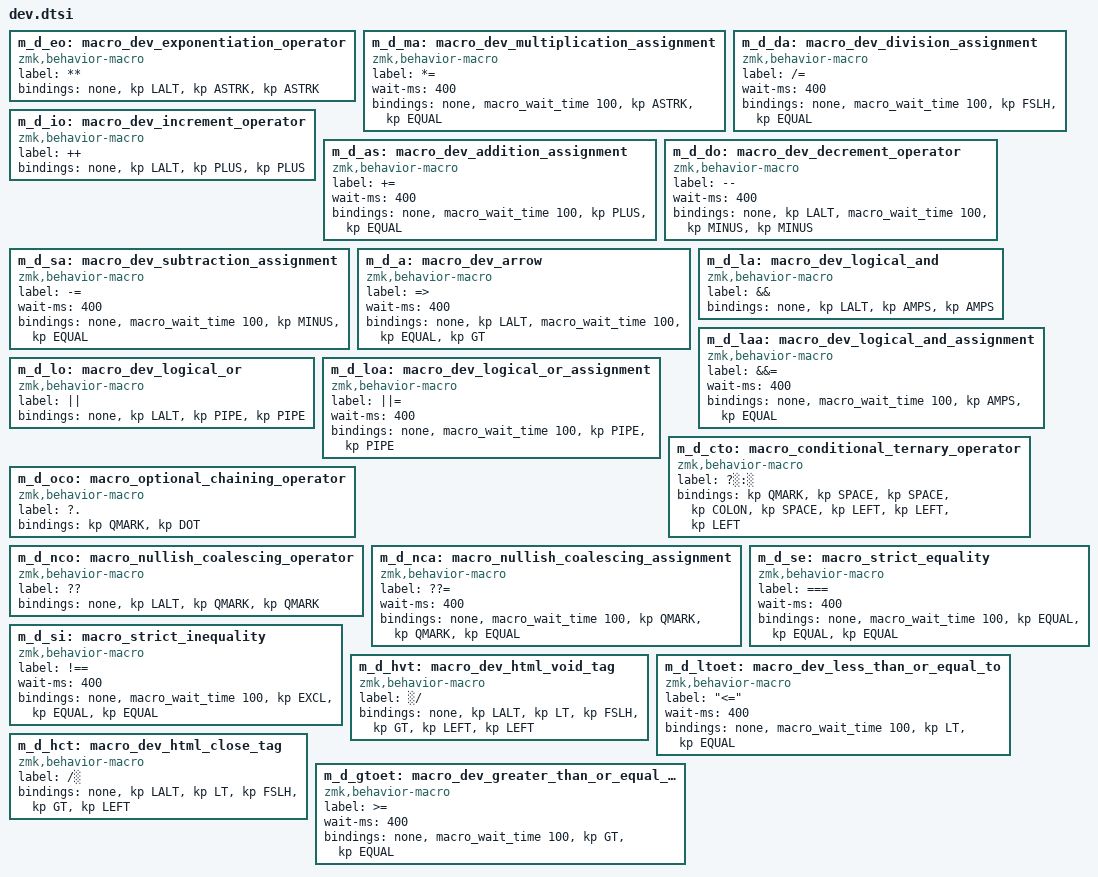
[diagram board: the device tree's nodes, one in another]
m_d_eo: macro_dev_exponentiation_operator {
    compatible = "zmk,behavior-macro";
    label = "**";
    #binding-cells = <0>;
    bindings
        = <&none &kp LALT> /* ALT fix for VSCode */
        , <&kp ASTRK &kp ASTRK>;
};

m_d_ma: macro_dev_multiplication_assignment {
    compatible = "zmk,behavior-macro";
    label = "*=";
    #binding-cells = <0>;
    wait-ms = <400>;
    bindings
        = <&none>
        , <&macro_wait_time 100>
        , <&kp ASTRK &kp EQUAL>;
};

m_d_da: macro_dev_division_assignment {
    compatible = "zmk,behavior-macro";
    label = "/=";
    #binding-cells = <0>;
    wait-ms = <400>;
    bindings
        = <&none>
        , <&macro_wait_time 100>
        , <&kp FSLH &kp EQUAL>;
};

m_d_io: macro_dev_increment_operator {
    compatible = "zmk,behavior-macro";
    label = "++";
    #binding-cells = <0>;
    bindings
        = <&none &kp LALT> /* ALT fix for VSCode */
        , <&kp PLUS &kp PLUS>;
};

m_d_as: macro_dev_addition_assignment {
    compatible = "zmk,behavior-macro";
    label = "+=";
    #binding-cells = <0>;
    wait-ms = <400>;
    bindings
        = <&none>
        , <&macro_wait_time 100>
        , <&kp PLUS &kp EQUAL>;
};

m_d_do: macro_dev_decrement_operator {
    compatible = "zmk,behavior-macro";
    label = "--";
    #binding-cells = <0>;
    wait-ms = <400>;
    bindings
        = <&none &kp LALT> /* ALT fix for VSCode */
        , <&macro_wait_time 100>
        , <&kp MINUS &kp MINUS>;
};

m_d_sa: macro_dev_subtraction_assignment {
    compatible = "zmk,behavior-macro";
    label = "-=";
    #binding-cells = <0>;
    wait-ms = <400>;
    bindings
        = <&none>
        , <&macro_wait_time 100>
        , <&kp MINUS &kp EQUAL>;
};

m_d_a: macro_dev_arrow {
    compatible = "zmk,behavior-macro";
    label = "=>";
    #binding-cells = <0>;
    wait-ms = <400>;
    bindings
        = <&none &kp LALT> /* ALT fix for VSCode */
        , <&macro_wait_time 100>
        , <&kp EQUAL &kp GT>;
};

m_d_la: macro_dev_logical_and {
    compatible = "zmk,behavior-macro";
    label = "&&";
    #binding-cells = <0>;
    bindings
        = <&none &kp LALT> /* ALT fix for VSCode */
        , <&kp AMPS &kp AMPS>;
};

m_d_laa: macro_dev_logical_and_assignment {
    compatible = "zmk,behavior-macro";
    label = "&&=";
    #binding-cells = <0>;
    wait-ms = <400>;
    bindings
        = <&none>
        , <&macro_wait_time 100>
        , <&kp AMPS &kp EQUAL>;
};

m_d_lo: macro_dev_logical_or {
    compatible = "zmk,behavior-macro";
    label = "||";
    #binding-cells = <0>;
    bindings
        = <&none &kp LALT> /* ALT fix for VSCode */
        , <&kp PIPE &kp PIPE>;
};

m_d_loa: macro_dev_logical_or_assignment {
    compatible = "zmk,behavior-macro";
    label = "||=";
    #binding-cells = <0>;
    wait-ms = <400>;
    bindings
        = <&none>
        , <&macro_wait_time 100>
        , <&kp PIPE &kp PIPE>;
};

m_d_cto: macro_conditional_ternary_operator {
    compatible = "zmk,behavior-macro";
    label = "?░:░";
    #binding-cells = <0>;
    bindings
        = <&kp QMARK &kp SPACE &kp SPACE &kp COLON &kp SPACE>
        , <&kp LEFT &kp LEFT &kp LEFT>;
};

m_d_oco: macro_optional_chaining_operator {
    compatible = "zmk,behavior-macro";
    label = "?.";
    #binding-cells = <0>;
    bindings
        = <&kp QMARK &kp DOT>;
};

m_d_nco: macro_nullish_coalescing_operator {
    compatible = "zmk,behavior-macro";
    label = "??";
    #binding-cells = <0>;
    bindings
        = <&none &kp LALT> /* ALT fix for VSCode */
        , <&kp QMARK &kp QMARK>;
};

m_d_nca: macro_nullish_coalescing_assignment {
    compatible = "zmk,behavior-macro";
    label = "??=";
    #binding-cells = <0>;
    wait-ms = <400>;
    bindings
        = <&none>
        , <&macro_wait_time 100>
        , <&kp QMARK &kp QMARK &kp EQUAL>;
};

m_d_se: macro_strict_equality {
    compatible = "zmk,behavior-macro";
    label = "===";
    #binding-cells = <0>;
    wait-ms = <400>;
    bindings
        = <&none>
        , <&macro_wait_time 100>
        , <&kp EQUAL &kp EQUAL &kp EQUAL>;
};

m_d_si: macro_strict_inequality {
    compatible = "zmk,behavior-macro";
    label = "!==";
    #binding-cells = <0>;
    wait-ms = <400>;
    bindings
        = <&none>
        , <&macro_wait_time 100>
        , <&kp EXCL &kp EQUAL &kp EQUAL>;
};

m_d_hvt: macro_dev_html_void_tag {
    compatible = "zmk,behavior-macro";
    label = "<░/>";
    #binding-cells = <0>;
    bindings
        = <&none &kp LALT> /* ALT fix for VSCode */
        , <&kp LT &kp FSLH &kp GT>
        , <&kp LEFT &kp LEFT>;
};

m_d_ltoet: macro_dev_less_than_or_equal_to {
    compatible = "zmk,behavior-macro";
    label = "<=";
    #binding-cells = <0>;
    wait-ms = <400>;
    bindings
        = <&none>
        , <&macro_wait_time 100>
        , <&kp LT &kp EQUAL>;
};

m_d_hct: macro_dev_html_close_tag {
    compatible = "zmk,behavior-macro";
    label = "</░>";
    #binding-cells = <0>;
    bindings
        = <&none &kp LALT> /* ALT fix for VSCode */
        , <&kp LT &kp FSLH &kp GT>
        , <&kp LEFT>;
};

m_d_gtoet: macro_dev_greater_than_or_equal_to {
    compatible = "zmk,behavior-macro";
    label = ">=";
    #binding-cells = <0>;
    wait-ms = <400>;
    bindings
        = <&none>
        , <&macro_wait_time 100>
        , <&kp GT &kp EQUAL>;
};
